# Template register map
Vendor: VendorName Co.Ltd; Series: SeriesName; File version: 1.2
CPU: CM7 r0p1, little endian, MPU, FPU, 4 interrupt priority bits
Registers are 32-bit, read-write, no defined reset value unless marked. A register's access mark holds for its fields unless they carry their own. Offsets are from the block's base; [hi:lo] are bit positions.

## EQEP1 — Enhanced Quadrature Encoder Pulse 1
Base 0x4001F000
Same registers: EQEP2 0x4001F200, EQEP3 0x4001F400, EQEP4 0x4001F600, EQEP5 0x4001F800, EQEP6 0x4001FA00
0x00 QPOSCNT ro — EQEP position counter register
  [31:0] QPOSCNT — EQEP QPOSCNT[31:0] bit: QEP position counter
0x04 QPOSINIT — EQEP position counter init register
  [31:0] QPOSINIT — EQEP QPOSINIT[31:0] bit: QEP position counter init
0x08 QPOSMAX — EQEP maximum position count register
  [31:0] QPOSMAX — EQEP QPOSMAX[31:0] bit: QEP maximum position count
0x0C QPOSCMP — EQEP position compare register
  [31:0] QPOSCMP — EQEP QPOSCMP[31:0] bit: QEP position compare
0x10 QPOSILAT ro — EQEP index position latch register
  [31:0] QPOSILAT — EQEP QPOSILAT[31:0] bit: QEP index position latch
0x14 QPOSSLAT ro — EQEP strobe position latch register
  [31:0] QPOSSLAT — EQEP QPOSSLAT[31:0] bit: QEP strobe position latch
0x18 QPOSLAT ro — EQEP position latch register
  [31:0] QPOSLAT — EQEP QPOSLAT[31:0] bit: QEP position latch
0x1C QUTMR ro — EQEP QEP unit timer register
  [31:0] QUTMR — EQEP QUTMR[31:0] bit: QEP unit timer
0x20 QUPRD — EQEP QEP unit period register
  [31:0] QUPRD — EQEP QUPRD[31:0] bit: QEP unit period
0x24 QWDTMR ro — EQEP QEP watchdog timer
  [15:0] QWDTMR — EQEP QWDTMR[15:0] bit: QEP watchdog timer
0x28 QWDPRD — EQEP QEP watchdog period register
  [15:0] QWDPRD — EQEP QWDPRD[15:0] bit: QEP watchdog period
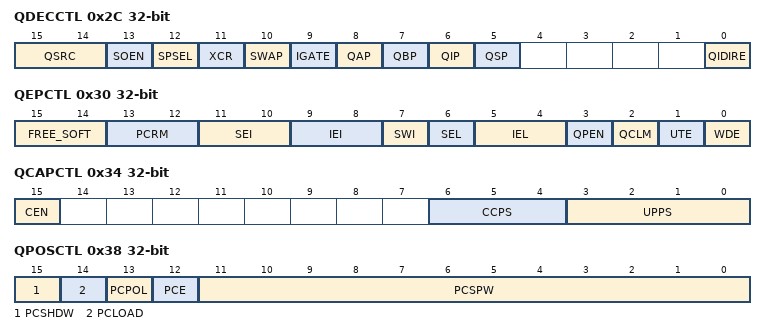
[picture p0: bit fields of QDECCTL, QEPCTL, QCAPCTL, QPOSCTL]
0x2C QDECCTL — EQEP quadrature decoder control register
  [15:14] QSRC — EQEP QSRC[1:0] bit: position-counter source selection
  [13] SOEN — EQEP SOEN bit: sync output-enable
  [12] SPSEL — EQEP SPSEL bit: sync output pin selection
  [11] XCR — EQEP XCR bit: external clock rate
  [10] SWAP — EQEP SWAP bit: CLK or DIR signal source for position counter
  [9] IGATE — EQEP IGATE bit: index pulse gating option
  [8] QAP — EQEP QAP bit: QEPA input polarity
  [7] QBP — EQEP QBP bit: QEPB input polarity
  [6] QIP — EQEP QIP bit: QEPI input polarity
  [5] QSP — EQEP QSP bit: QEPS input polarity
  [0] QIDIRE — EQEP QIDIRE bit: only internal testing use
0x30 QEPCTL — EQEP QEP control register
  [15:14] FREE_SOFT — EQEP FREE_SOFT[1:0] bit: emulation mode
  [13:12] PCRM — EQEP PCRM[1:0] bit: postion counter reset
  [11:10] SEI — EQEP SEI[1:0] bit: strobe event initialization of position counter
  [9:8] IEI — EQEP IEI[1:0] bit: index event init of position count
  [7] SWI — EQEP SWI bit: software init position counter
  [6] SEL — EQEP SEL bit: strobe event latch of position counter
  [5:4] IEL — EQEP IEL[1:0] bit: index event latch of position counter
  [3] QPEN — EQEP QPEN bit: quadrature position counter enable
  [2] QCLM — EQEP QCLM bit: QEP capture latch mode
  [1] UTE — EQEP UTE bit: QEP unit timer enable
  [0] WDE — EQEP WDE bit: QEP watchdog enable
0x34 QCAPCTL — EQEP qaudrature capture control register
  [15] CEN — EQEP CEN bit: enable eQEP capture
  [6:4] CCPS — EQEP CCPS[2:0] bit: eQEP capture timer clock prescaler
  [3:0] UPPS — EQEP UPPS[3:0] bit: unit position event prescaler
0x38 QPOSCTL — EQEP position compare control register
  [15] PCSHDW — EQEP PCSHDW bit: position compare of shadow enable
  [14] PCLOAD — EQEP PCLOAD bit: position compare of shadow load
  [13] PCPOL — EQEP PCPOL bit: polarity of sync output
  [12] PCE — EQEP PCE bit: position compare enable or disable
  [11:0] PCSPW — EQEP PCSPW[11:0] bit: select-position-compare sync output pulse width
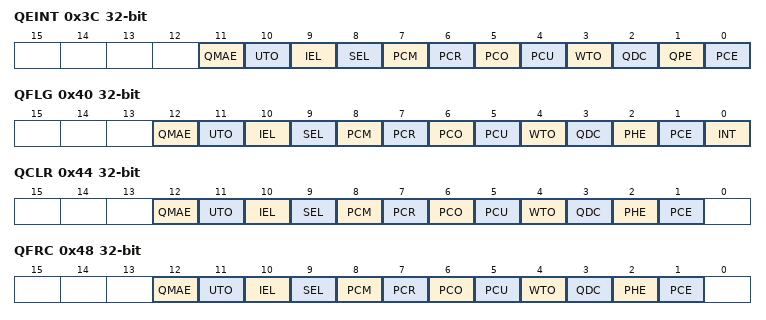
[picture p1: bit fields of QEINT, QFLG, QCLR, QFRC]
0x3C QEINT — EQEP QEP interrupt control register
  [11] QMAE — EQEP QMAE bit: QMA error interrupt enable
  [10] UTO — EQEP UTO bit: unit time out interrupt enable
  [9] IEL — EQEP IEL bit: index event latch interrupt enable
  [8] SEL — EQEP SEL bit: strobe event latch interrupt enable
  [7] PCM — EQEP PCM bit: position-compare match interrupt enable
  [6] PCR — EQEP PCR bit: position-compare ready interrupt enable
  [5] PCO — EQEP PCO bit: position counter overflow interrupt enable
  [4] PCU — EQEP PCU bit: position counter underflow interrupt enable
  [3] WTO — EQEP WTO bit: watchdog time out interrupt enable
  [2] QDC — EQEP QDC bit: quadrature direction change interrupt enable
  [1] QPE — EQEP QPE bit: quadrature phase error interrupt enable
  [0] PCE — EQEP PCE bit: position counter error interrupt enable
0x40 QFLG ro — EQEP QEP interrupt flag register
  [12] QMAE — EQEP QMAE bit: QMA error interrupt flag
  [11] UTO — EQEP UTO bit: unit time out interrupt flag
  [10] IEL — EQEP IEL bit: index event latch interrupt flag
  [9] SEL — EQEP SEL bit: strobe event latch interrupt flag
  [8] PCM — EQEP PCM bit: eQEP compare match event interrupt flag
  [7] PCR — EQEP PCR bit: position-compare ready interrupt flag
  [6] PCO — EQEP PCO bit: position counter overflow interrupt flag
  [5] PCU — EQEP PCU bit: position counter underflow interrupt flag
  [4] WTO — EQEP WTO bit: watchdog timeout interrupt flag
  [3] QDC — EQEP QDC bit: quadrature direction change interrupt flag
  [2] PHE — EQEP PHE bit: quadrature phase error interrupt flag
  [1] PCE — EQEP PCE bit: position counter error interrupt flag
  [0] INT — EQEP INT bit: global interrupt status flag
0x44 QCLR — EQEP QEP interrupt clear register
  [12] QMAE — EQEP QMAE bit: clear QMA error interrupt flag
  [11] UTO — EQEP UTO bit: clear unit time out interrupt flag
  [10] IEL — EQEP IEL bit: clear index event latch interrupt flag
  [9] SEL — EQEP SEL bit: clear strobe event latch interrupt flag
  [8] PCM — EQEP PCM bit: clear eQEP compare match event interrupt flag
  [7] PCR — EQEP PCR bit: clear position-compare ready interrupt flag
  [6] PCO — EQEP PCO bit: clear position counter overflow interrupt flag
  [5] PCU — EQEP PCU bit: clear position counter underflow interrupt flag
  [4] WTO — EQEP WTO bit: clear watchdog timeout interrupt flag
  [3] QDC — EQEP QDC bit: clear quadrature direction change interrupt flag
  [2] PHE — EQEP PHE bit: clear quadrature phase error interrupt flag
  [1] PCE — EQEP PCE bit: clear position counter error interrupt flag
0x48 QFRC — EQEP QEP interrupt force register
  [12] QMAE — EQEP QMAE bit: force QMA error interrupt
  [11] UTO — EQEP UTO bit: force unit time out interrupt
  [10] IEL — EQEP IEL bit: force index event latch interrupt
  [9] SEL — EQEP SEL bit: force strobe event latch interrupt
  [8] PCM — EQEP PCM bit: force position-compare match interrupt
  [7] PCR — EQEP PCR bit: force position-compare ready interrupt
  [6] PCO — EQEP PCO bit: force position counter overflow interrupt
  [5] PCU — EQEP PCU bit: force position counter underflow interrupt
  [4] WTO — EQEP WTO bit: force watchdog time out interrupt
  [3] QDC — EQEP QDC bit: force quadrature direction change interrupt
  [2] PHE — EQEP PHE bit: force quadrature phase error interrupt
  [1] PCE — EQEP PCE bit: force position counter error interrupt
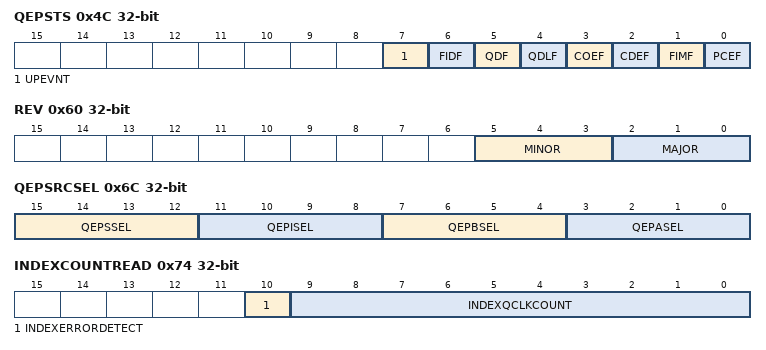
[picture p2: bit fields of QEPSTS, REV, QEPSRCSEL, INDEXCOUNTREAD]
0x4C QEPSTS — EQEP QEP status register
  [7] UPEVNT — EQEP UPEVNT bit: unit position event flag
  [6] FIDF ro — EQEP FIDF bit: direction on the first index marker
  [5] QDF ro — EQEP QDF bit: quadrature direction flag
  [4] QDLF ro — EQEP QDLF bit: eQEP direction latch flag
  [3] COEF — EQEP COEF bit: capture overflow error flag
  [2] CDEF — EQEP CDEF bit: capture direction error flag
  [1] FIMF — EQEP FIMF bit: first index marker flag
  [0] PCEF ro — EQEP PCEF bit: position counter error flag
0x50 QCTMR ro — EQEP QEP capture timer register
  [15:0] QCTMR — EQEP QCTMR[15:0] bit: this register provides time base for edge capture unit
0x54 QCPRD ro — EQEP QEP capture period register
  [15:0] QCPRD — EQEP QCPRD[15:0] bit: this register holds the period count value between the last successive eQEP position events
0x58 QCTMRLAT ro — EQEP QEP capture latch register
  [15:0] QCTMRLAT — EQEP QCTMRLAT[15:0] bit: eQEP capture timer value
0x5C QCPRDLAT ro — EQEP QEP capture period latch register
  [15:0] QCPRDLAT — EQEP QCPRDLAT[15:0] bit: eQEP capture periodic count value
0x60 REV — EQEP QEP revision number register
  [5:3] MINOR — EQEP MINOR[2:0] bit: this field specifies the minor revision number for the eQEP IP
  [2:0] MAJOR — EQEP MAJOR[2:0] bit: this field specifies the major revision number for the eQEP IP
0x64 QEPSTROBESEL — EQEP QEP strobe select register
  [1:0] STROBESEL — EQEP STROBESEL[1:0] bit: strobe source select
0x68 QMACTRL — EQEP QMA control register
  [2:0] MODE — EQEP MODE[2:0] bit: select mode for QMA mode
0x6C QEPSRCSEL — EQEP QEP source select register
  [15:12] QEPSSEL — EQEP QEPSSEL[3:0] bit: QEP strobe source select
  [11:8] QEPISEL — EQEP QEPISEL[3:0] bit: QEP index source select
  [7:4] QEPBSEL — EQEP QEPBSEL[3:0] bit: QEPB source select
  [3:0] QEPASEL — EQEP QEPASEL[3:0] bit: QEPA source select
0x70 INDEXCOUNTMAX — EQEP QEP INDEX max count register
  [9:0] INDEXCOUNTMAX — EQEP INDEXCOUNTMAX[9:0] bit: QEP INDEX count max value
0x74 INDEXCOUNTREAD ro — EQEP QEP INDEX real-time count register
  [10] INDEXERRORDETECT — EQEP INDEXERRORDETECT bit: INDEX error detect
  [9:0] INDEXQCLKCOUNT — EQEP INDEXQCLKCOUNT[9:0] bit: INDEX Qclk real-time count value
